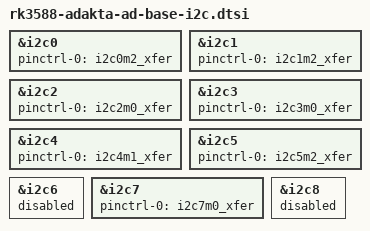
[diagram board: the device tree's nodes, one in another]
// SPDX-License-Identifier: (GPL-2.0+ OR MIT)
/*
 * Copyright (c) 2024 Adakta, Ltd.
 *
 */

&i2c0 {
	pinctrl-names = "default";
	pinctrl-0 = <&i2c0m2_xfer>;
	status = "okay";
};

&i2c1 {
	pinctrl-names = "default";
	pinctrl-0 = <&i2c1m2_xfer>;
	status = "okay";
};

&i2c2 {
	pinctrl-names = "default";
	pinctrl-0 = <&i2c2m0_xfer>;
	status = "okay";
};

&i2c3 {
	pinctrl-names = "default";
	pinctrl-0 = <&i2c3m0_xfer>;
	status = "okay";
};

&i2c4 {
	pinctrl-names = "default";
	pinctrl-0 = <&i2c4m1_xfer>;
	status = "okay";
};

&i2c5 {
	pinctrl-names = "default";
	pinctrl-0 = <&i2c5m2_xfer>;
	status = "okay";
};

&i2c6 {
	status = "disabled";
};

&i2c7 {
	pinctrl-names = "default";
	pinctrl-0 = <&i2c7m0_xfer>;
	status = "okay";
};

&i2c8 {
	status = "disabled";
};
